# GD32M53x register map
File version: 1.0
CPU: CM33 r2p1, little endian, MPU, FPU, DSP, 4 interrupt priority bits
Registers are 32-bit, read-write, reset 0x0 unless marked. A register's access mark holds for its fields unless they carry their own. Offsets are from the block's base; [hi:lo] are bit positions; lines under a group give offsets from that group; {n}, {i} and the like mark numbered series.

## EVIC — Event interconnection unit
Base 0x40018400
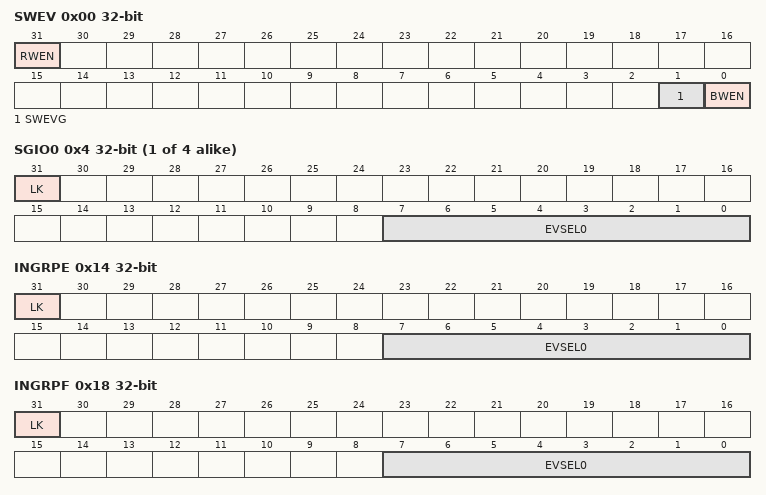
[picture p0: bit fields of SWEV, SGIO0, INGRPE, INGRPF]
0x00 SWEV — Software event register
  [31] RWEN — EVIC_SWEV register write enable
  [1] SWEVG — Software event generation
  [0] BWEN — SWEVG bit write enable
{0x4+4i} SGIO{i} (i=0..3) — Event interconnect for single I/O register {i}
  [31] LK — EVIC_SGIOx register lock.
  [7:0] EVSEL0 — Event source selection for single I/O
0x14 INGRPE — Event interconnect for input group E register
  [31] LK — EVIC_INGRPE register lock.
  [7:0] EVSEL0 — Event source selection for group E I/O input
0x18 INGRPF — Event interconnect for input group F register
  [31] LK — EVIC_INGRPF register lock.
  [7:0] EVSEL0 — Event source selection for group F I/O input
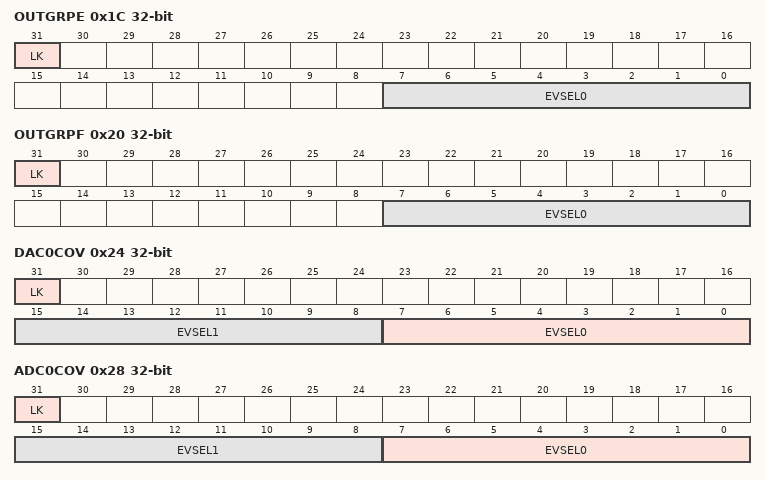
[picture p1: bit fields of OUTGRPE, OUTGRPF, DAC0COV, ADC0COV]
0x1C OUTGRPE — Event interconnect for output group E register
  [31] LK — EVIC_OUTGRPE register lock.
  [7:0] EVSEL0 — Event source selection for group E I/O output
0x20 OUTGRPF — Event interconnect for output group F register
  [31] LK — EVIC_OUTGRPF register lock.
  [7:0] EVSEL0 — Event source selection for group F I/O output
0x24 DAC0COV — Event interconnect for DAC0 conversion register
  [31] LK — EVIC_DAC0COV register lock.
  [15:8] EVSEL1 — Event source selection for DAC0_OUT1 conversion
  [7:0] EVSEL0 — Event source selection for DAC0_OUT0 conversion
0x28 ADC0COV — Event interconnect for ADC0 conversion register
  [31] LK — EVIC_ADC0COV register lock.
  [15:8] EVSEL1 — Event source selection 1 for ADC0 group conversion
  [7:0] EVSEL0 — Event source selection 0 for ADC0 group conversion
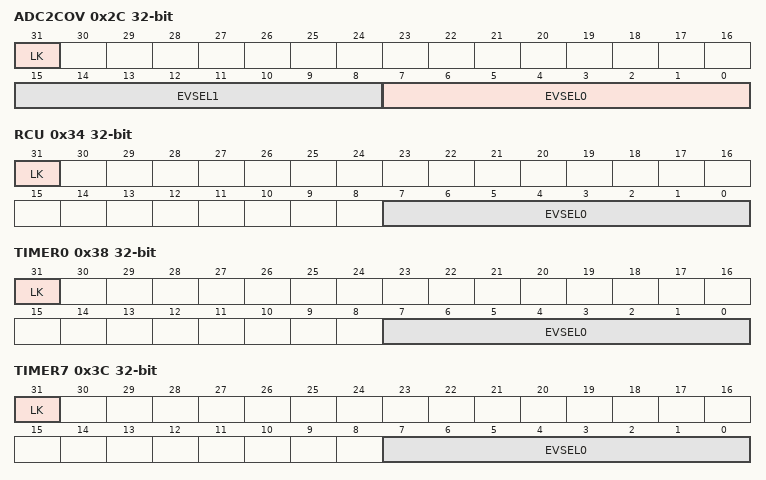
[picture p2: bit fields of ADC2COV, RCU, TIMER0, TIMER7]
0x2C ADC2COV — Event interconnect for ADC2 conversion register
  [31] LK — EVIC_ADC2COV register lock.
  [15:8] EVSEL1 — Event source selection 1 for ADC2 group conversion
  [7:0] EVSEL0 — Event source selection 0 for ADC2 group conversion
0x34 RCU — Event interconnect for RCU register
  [31] LK — EVIC_RCU register lock.
  [7:0] EVSEL0 — Event source selection for IRC32M switching
0x38 TIMER0 — Event interconnect for TIMER0 register
  [31] LK — EVIC_TIMER0 register lock.
  [7:0] EVSEL0 — Event source selection for TIMER0 slave mode.
0x3C TIMER7 — Event interconnect for TIMER7 register
  [31] LK — EVIC_TIMER7 register lock.
  [7:0] EVSEL0 — Event source selection for TIMER7 slave mode.
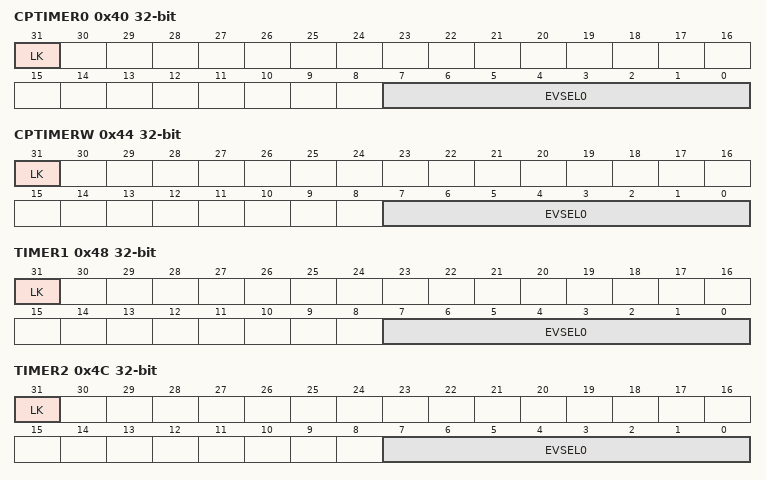
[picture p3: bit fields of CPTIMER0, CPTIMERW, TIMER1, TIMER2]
0x40 CPTIMER0 — Event interconnect for CPTIMER0 register
  [31] LK — EVIC_CPTIMER0 register lock.
  [7:0] EVSEL0 — Event source selection for CPTIMER0 slave mode
0x44 CPTIMERW — Event interconnect for CPTIMERW register
  [31] LK — EVIC_CPTIMERW register lock.
  [7:0] EVSEL0 — Event source selection for CPTIMERW slave mode
0x48 TIMER1 — Event interconnect for TIMER1 register
  [31] LK — EVIC_TIMER1 register lock.
  [7:0] EVSEL0 — Event input source selection for TIMER1 slave mode trigger
0x4C TIMER2 — Event interconnect for TIMER2 register
  [31] LK — EVIC_TIMER2 register lock.
  [7:0] EVSEL0 — Event source selection for TIMER2 slave mode
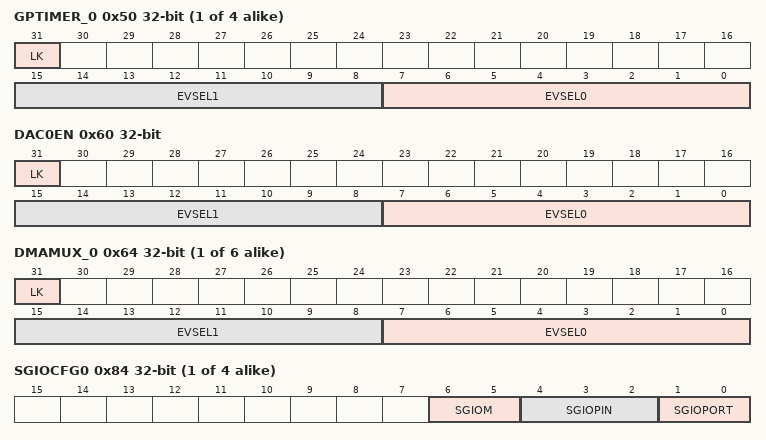
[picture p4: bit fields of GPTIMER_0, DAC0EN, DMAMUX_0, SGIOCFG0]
{0x50+4i} GPTIMER_{i} (i=0..3) — Event interconnect for GPTIMER register {i}
  [31] LK — EVIC_GPTIMER_{i} register lock.
  [15:8] EVSEL{2i+1} — Event source selection {2i+1} for GPTIMER slave mode
  [7:0] EVSEL{2i} — Event source selection {2i} for GPTIMER slave mode
0x60 DAC0EN — Event interconnect for DAC0 enable register
  [31] LK — EVIC_DAC0EN register lock.
  [15:8] EVSEL1 — Event source selection for enabling DAC0_OUT1
  [7:0] EVSEL0 — Event source selection for enabling DAC0_OUT0
{0x64+4i} DMAMUX_{i} (i=0..5) — Event interconnect for DMAMUX register {i}
  [31] LK — EVIC_DMAMUX_{i} register lock.
  [15:8] EVSEL{2i+1} — Event source selection {2i+1} for DMAMUX
  [7:0] EVSEL{2i} — Event source selection {2i} for DMAMUX
0x7C SMCFG0 reset 0x3 — Slave mode configuration register 0
  [1:0] CPTIMER0_SMSEL — CPTIMER0 slave mode selection
0x80 SMCFG1 reset 0x3 — Slave mode configuration register 1
  [1:0] CPTIMERW_SMSEL — CPTIMERW slave mode selection
{0x84+4i} SGIOCFG{i} (i=0..3) — Single I/O configuration register {i}
  [6:5] SGIOM — Single I/O mode
  [4:2] SGIOPIN — Single I/O pin
  [1:0] SGIOPORT — Single I/O port
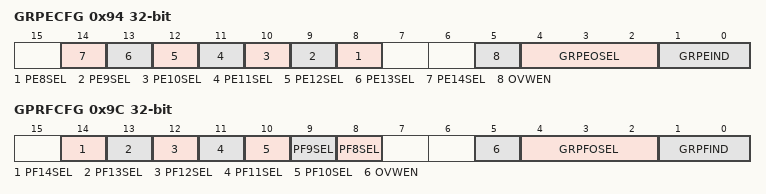
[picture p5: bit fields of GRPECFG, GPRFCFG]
0x94 GRPECFG — Group E configuration register
  [n] PE{n}SEL (n=8..14) — PE{n} pin selection
  [5] OVWEN — EVIC_GRPEDH register overwrite enable
  [4:2] GRPEOSEL — Group E output selection
  [1:0] GRPEIND — Group E input detection
0x98 GRPEDH — Group E data holding register
  [6:0] GRPE_DH — Group E holding data
0x9C GPRFCFG — Group F configuration register
  [14] PF14SEL — PF14 pin selection
  [13] PF13SEL — PF13 pin selection
  [12] PF12SEL — PF12 pin selection
  [11] PF11SEL — PE11 pin selection
  [10] PF10SEL — PF10 pin selection
  [9] PF9SEL — PF9 pin selection
  [8] PF8SEL — PF8 pin selection
  [5] OVWEN — EVIC_GRPFDH register overwrite enable
  [4:2] GRPFOSEL — Group F output selection
  [1:0] GRPFIND — Group F input detection
0x100 GRPFDH — Group F data holding register
  [6:0] GRPF_DH — Group F holding data
